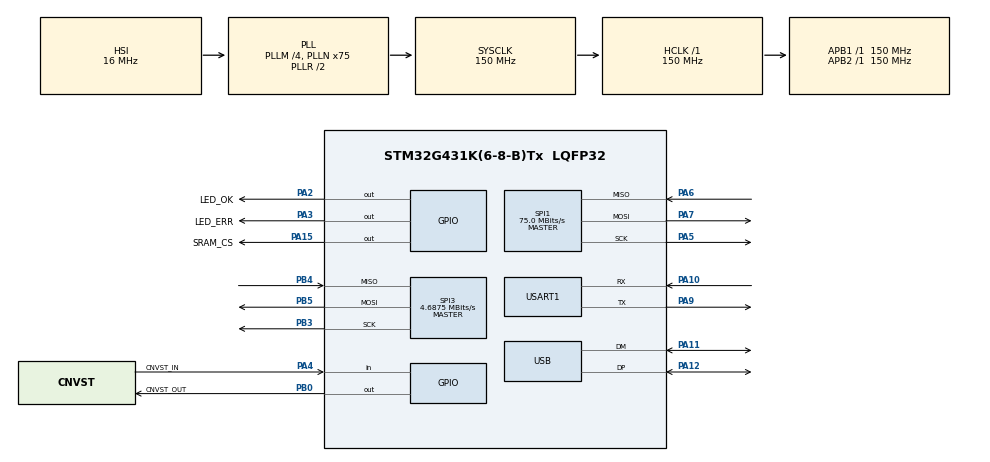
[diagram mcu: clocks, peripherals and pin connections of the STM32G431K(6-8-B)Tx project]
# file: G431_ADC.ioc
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Mcu.Family=STM32G4
Mcu.Name=STM32G431K(6-8-B)Tx
Mcu.Package=LQFP32
NVIC.PriorityGroup=NVIC_PRIORITYGROUP_4
NVIC.USB_LP_IRQn=true\:0\:0\:false\:false\:true\:false\:true\:true
PA10.GPIO_Speed=GPIO_SPEED_FREQ_VERY_HIGH
PA10.Mode=Asynchronous
PA10.Signal=USART1_RX
PA11.Mode=Device
PA11.Signal=USB_DM
PA12.Mode=Device
PA12.Signal=USB_DP
PA13.Mode=Serial_Wire
PA13.Signal=SYS_JTMS-SWDIO
PA14.Mode=Serial_Wire
PA14.Signal=SYS_JTCK-SWCLK
PA15.GPIO_Label=SRAM_CS
PA15.GPIO_Speed=GPIO_SPEED_FREQ_VERY_HIGH
PA15.Signal=GPIO_Output
PA2.GPIO_Label=LED_OK
PA2.Signal=GPIO_Output
PA3.GPIO_Label=LED_ERR
PA3.Signal=GPIO_Output
PA4.GPIO_Label=CNVST_IN
PA4.Signal=GPIO_Input
PA5.GPIO_Speed=GPIO_SPEED_FREQ_VERY_HIGH
PA5.Mode=Full_Duplex_Master
PA5.Signal=SPI1_SCK
PA6.GPIO_Speed=GPIO_SPEED_FREQ_VERY_HIGH
PA6.Mode=Full_Duplex_Master
PA6.Signal=SPI1_MISO
PA7.GPIO_Speed=GPIO_SPEED_FREQ_VERY_HIGH
PA7.Mode=Full_Duplex_Master
PA7.Signal=SPI1_MOSI
PA9.GPIO_Speed=GPIO_SPEED_FREQ_VERY_HIGH
PA9.Mode=Asynchronous
PA9.Signal=USART1_TX
PB0.GPIO_Label=CNVST_OUT
PB0.GPIO_Speed=GPIO_SPEED_FREQ_VERY_HIGH
PB0.PinState=GPIO_PIN_RESET
PB0.Signal=GPIO_Output
PB3.GPIO_Speed=GPIO_SPEED_FREQ_VERY_HIGH
PB3.Mode=Full_Duplex_Master
PB3.Signal=SPI3_SCK
PB4.GPIO_Speed=GPIO_SPEED_FREQ_VERY_HIGH
PB4.Mode=Full_Duplex_Master
PB4.Signal=SPI3_MISO
PB5.GPIO_Speed=GPIO_SPEED_FREQ_VERY_HIGH
PB5.Mode=Full_Duplex_Master
PB5.Signal=SPI3_MOSI
ProjectManager.HeapSize=0x200
ProjectManager.StackSize=0x400
ProjectManager.TargetToolchain=Makefile
RCC.ADC12Freq_Value=150000000
RCC.AHBFreq_Value=150000000
RCC.APB1Freq_Value=150000000
RCC.APB1TimFreq_Value=150000000
RCC.APB2Freq_Value=150000000
RCC.APB2TimFreq_Value=150000000
RCC.CK48CLockSelection=RCC_USBCLKSOURCE_HSI48
RCC.CortexFreq_Value=150000000
RCC.EXTERNAL_CLOCK_VALUE=12288000
RCC.HCLKFreq_Value=150000000
RCC.HSE_VALUE=12000000
RCC.HSI48_VALUE=48000000
RCC.HSI_VALUE=16000000
RCC.LSE_VALUE=32768
RCC.PLLM=RCC_PLLM_DIV4
RCC.PLLN=75
RCC.PREFETCH_ENABLE=1
RCC.SYSCLKFreq_VALUE=150000000
RCC.SYSCLKSource=RCC_SYSCLKSOURCE_PLLCLK
RCC.USBFreq_Value=48000000
RCC.VCOOutputFreq_Value=300000000
SPI1.BaudRatePrescaler=SPI_BAUDRATEPRESCALER_2
SPI1.CLKPhase=SPI_PHASE_2EDGE
SPI1.CLKPolarity=SPI_POLARITY_HIGH
SPI1.CalculateBaudRate=75.0 MBits/s
SPI1.DataSize=SPI_DATASIZE_16BIT
SPI1.Direction=SPI_DIRECTION_2LINES
SPI1.Mode=SPI_MODE_MASTER
SPI1.VirtualType=VM_MASTER
SPI3.BaudRatePrescaler=SPI_BAUDRATEPRESCALER_32
SPI3.CLKPhase=SPI_PHASE_2EDGE
SPI3.CLKPolarity=SPI_POLARITY_HIGH
SPI3.CalculateBaudRate=4.6875 MBits/s
SPI3.DataSize=SPI_DATASIZE_16BIT
SPI3.Direction=SPI_DIRECTION_2LINES
SPI3.Mode=SPI_MODE_MASTER
SPI3.VirtualType=VM_MASTER
TIM6.AutoReloadPreload=TIM_AUTORELOAD_PRELOAD_ENABLE
TIM6.PeriodNoDither=149
TIM6.TIM_MasterOutputTrigger=TIM_TRGO_UPDATE
USART1.VirtualMode-Asynchronous=VM_ASYNC
USB_DEVICE.CLASS_NAME_FS=CDC
USB_DEVICE.VirtualMode=Cdc
USB_DEVICE.VirtualModeFS=Cdc_FS
VP_SYS_VS_DBSignals.Mode=DisableDeadBatterySignals
VP_TIM1_VS_ClockSourceINT.Mode=Internal
VP_TIM2_VS_ClockSourceINT.Mode=Internal
VP_TIM6_VS_ClockSourceINT.Mode=Enable_Timer
VP_USB_DEVICE_VS_USB_DEVICE_CDC_FS.Mode=CDC_FS
board=custom

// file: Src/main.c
/* USER CODE BEGIN Header */
/**
 ******************************************************************************
 * @file           : main.c
 * @brief          : Main program body
 ******************************************************************************
 * @attention
 *
 * Copyright (c) 2022 STMicroelectronics.
 * All rights reserved.
 *
 * This software is licensed under terms that can be found in the LICENSE file
 * in the root directory of this software component.
 * If no LICENSE file comes with this software, it is provided AS-IS.
 *
 ******************************************************************************
 */
/* USER CODE END Header */
#include "main.h"
#include "spi.h"
#include "tim.h"
#include "usart.h"
#include "usb_device.h"
#include "gpio.h"

/* USER CODE BEGIN Includes */
#include "main_cycle.hpp"
/* USER CODE END Includes */

void SystemClock_Config(void);

int main(void)
{

    /* MCU Configuration--------------------------------------------------------*/

    /* Reset of all peripherals, Initializes the Flash interface and the Systick. */
    HAL_Init();

    /* Configure the system clock */
    SystemClock_Config();

    /* Initialize all configured peripherals */
    MX_GPIO_Init();
    MX_SPI1_Init();
    MX_SPI3_Init();
    MX_TIM2_Init();
    MX_TIM6_Init();
    MX_USART1_UART_Init();
    MX_USB_Device_Init();
    MX_TIM1_Init();

    /* Infinite loop */
    /* USER CODE BEGIN WHILE */
    main_loop();
    while (1) {
        /* USER CODE END WHILE */

    }
}

void SystemClock_Config(void)
{
    RCC_OscInitTypeDef RCC_OscInitStruct = {0};
    RCC_ClkInitTypeDef RCC_ClkInitStruct = {0};

    /** Configure the main internal regulator output voltage
     */
    HAL_PWREx_ControlVoltageScaling(PWR_REGULATOR_VOLTAGE_SCALE1);

    /** Initializes the RCC Oscillators according to the specified parameters
     * in the RCC_OscInitTypeDef structure.
     */
    RCC_OscInitStruct.OscillatorType = RCC_OSCILLATORTYPE_HSI | RCC_OSCILLATORTYPE_HSI48;
    RCC_OscInitStruct.HSIState = RCC_HSI_ON;
    RCC_OscInitStruct.HSICalibrationValue = RCC_HSICALIBRATION_DEFAULT;
    RCC_OscInitStruct.HSI48State = RCC_HSI48_ON;
    RCC_OscInitStruct.PLL.PLLState = RCC_PLL_ON;
    RCC_OscInitStruct.PLL.PLLSource = RCC_PLLSOURCE_HSI;
    RCC_OscInitStruct.PLL.PLLM = RCC_PLLM_DIV4;
    RCC_OscInitStruct.PLL.PLLN = 75;
    RCC_OscInitStruct.PLL.PLLP = RCC_PLLP_DIV2;
    RCC_OscInitStruct.PLL.PLLQ = RCC_PLLQ_DIV2;
    RCC_OscInitStruct.PLL.PLLR = RCC_PLLR_DIV2;
    if (HAL_RCC_OscConfig(&RCC_OscInitStruct) != HAL_OK) {
        Error_Handler();
    }

    /** Initializes the CPU, AHB and APB buses clocks
     */
    RCC_ClkInitStruct.ClockType = RCC_CLOCKTYPE_HCLK | RCC_CLOCKTYPE_SYSCLK
                                  | RCC_CLOCKTYPE_PCLK1 | RCC_CLOCKTYPE_PCLK2;
    RCC_ClkInitStruct.SYSCLKSource = RCC_SYSCLKSOURCE_PLLCLK;
    RCC_ClkInitStruct.AHBCLKDivider = RCC_SYSCLK_DIV1;
    RCC_ClkInitStruct.APB1CLKDivider = RCC_HCLK_DIV1;
    RCC_ClkInitStruct.APB2CLKDivider = RCC_HCLK_DIV1;

    if (HAL_RCC_ClockConfig(&RCC_ClkInitStruct, FLASH_LATENCY_4) != HAL_OK) {
        Error_Handler();
    }
}

void Error_Handler(void)
{
    __disable_irq();
    while (1) {
    }
}
